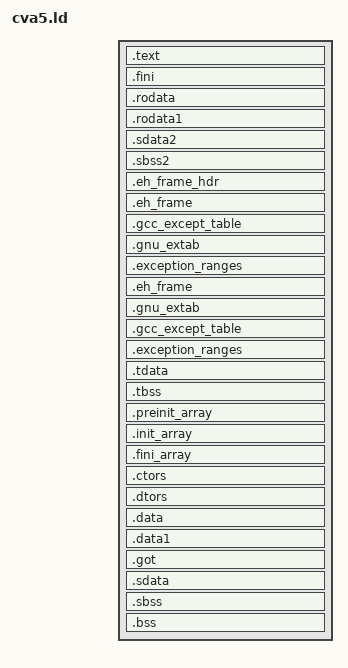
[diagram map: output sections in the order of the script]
/* Default linker script, for normal executables */
/* Copyright (C) 2014-2021 Free Software Foundation, Inc.
   Copying and distribution of this script, with or without modification,
   are permitted in any medium without royalty provided the copyright
   notice and this notice are preserved.  */
OUTPUT_ARCH(riscv)
ENTRY(_start)
/*STARTUP(crtbegin.o)*/
MEMORY
{
  ram : ORIGIN = (DEFINED(__mem_addr) ? __mem_addr : 0x80000000), LENGTH = (DEFINED(__mem_size) ? __mem_size : 128K)
}

SECTIONS
{
  PROVIDE(__stack = ORIGIN(ram) + LENGTH(ram));

  .text :
  {
    *(.text.start)
    *(.text.unlikely .text.unlikely.*)
    *(.text.startup .text.startup.*)
    *(.text .text.*)
    *(.gnu.linkonce.t.*)
  } > ram
  
  .fini           :
  {
    KEEP (*(SORT_NONE(.fini)))
  } > ram
  PROVIDE (__etext = .);
  PROVIDE (_etext = .);
  PROVIDE (etext = .);
  .rodata         : { *(.rodata .rodata.* .gnu.linkonce.r.*) } > ram
  .rodata1        : { *(.rodata1) } > ram
  .sdata2         :
  {
    *(.sdata2 .sdata2.* .gnu.linkonce.s2.*)
  } > ram
  .sbss2          : { *(.sbss2 .sbss2.* .gnu.linkonce.sb2.*) } > ram
  .eh_frame_hdr   : { *(.eh_frame_hdr) *(.eh_frame_entry .eh_frame_entry.*) } > ram
  .eh_frame       : ONLY_IF_RO { KEEP (*(.eh_frame)) *(.eh_frame.*) } > ram
  .gcc_except_table   : ONLY_IF_RO { *(.gcc_except_table .gcc_except_table.*) } > ram
  .gnu_extab   : ONLY_IF_RO { *(.gnu_extab*) } > ram
  /* These sections are generated by the Sun/Oracle C++ compiler.  */
  .exception_ranges   : ONLY_IF_RO { *(.exception_ranges*) } > ram
  /* Adjust the address for the data segment.  We want to adjust up to
     the same address within the page on the next page up.  */
  . = DATA_SEGMENT_ALIGN (CONSTANT (MAXPAGESIZE), CONSTANT (COMMONPAGESIZE));
  /* Exception handling  */
  .eh_frame       : ONLY_IF_RW { KEEP (*(.eh_frame)) *(.eh_frame.*) } > ram
  .gnu_extab      : ONLY_IF_RW { *(.gnu_extab) } > ram
  .gcc_except_table   : ONLY_IF_RW { *(.gcc_except_table .gcc_except_table.*) } > ram
  .exception_ranges   : ONLY_IF_RW { *(.exception_ranges*) } > ram
  /* Thread Local Storage sections  */
  .tdata	  :
   {
     PROVIDE_HIDDEN (__tdata_start = .);
     *(.tdata .tdata.* .gnu.linkonce.td.*)
   } > ram
  .tbss		  : { *(.tbss .tbss.* .gnu.linkonce.tb.*) *(.tcommon) } > ram
  .preinit_array    :
  {
    PROVIDE_HIDDEN (__preinit_array_start = .);
    KEEP (*(.preinit_array))
    PROVIDE_HIDDEN (__preinit_array_end = .);
  } > ram
  .init_array    :
  {
    PROVIDE_HIDDEN (__init_array_start = .);
    KEEP (*(SORT_BY_INIT_PRIORITY(.init_array.*) SORT_BY_INIT_PRIORITY(.ctors.*)))
    KEEP (*(.init_array EXCLUDE_FILE (*crtbegin.o *crtbegin?.o *crtend.o *crtend?.o ) .ctors))
    PROVIDE_HIDDEN (__init_array_end = .);
  } > ram
  .fini_array    :
  {
    PROVIDE_HIDDEN (__fini_array_start = .);
    KEEP (*(SORT_BY_INIT_PRIORITY(.fini_array.*) SORT_BY_INIT_PRIORITY(.dtors.*)))
    KEEP (*(.fini_array EXCLUDE_FILE (*crtbegin.o *crtbegin?.o *crtend.o *crtend?.o ) .dtors))
    PROVIDE_HIDDEN (__fini_array_end = .);
  } > ram
  .ctors          :
  {
    /* gcc uses crtbegin.o to find the start of
       the constructors, so we make sure it is
       first.  Because this is a wildcard, it
       doesn't matter if the user does not
       actually link against crtbegin.o; the
       linker won't look for a file to match a
       wildcard.  The wildcard also means that it
       doesn't matter which directory crtbegin.o
       is in.  */
    KEEP (*crtbegin.o(.ctors))
    KEEP (*crtbegin?.o(.ctors))
    /* We don't want to include the .ctor section from
       the crtend.o file until after the sorted ctors.
       The .ctor section from the crtend file contains the
       end of ctors marker and it must be last */
    KEEP (*(EXCLUDE_FILE (*crtend.o *crtend?.o ) .ctors))
    KEEP (*(SORT(.ctors.*)))
    KEEP (*(.ctors))
  } > ram
  .dtors          :
  {
    KEEP (*crtbegin.o(.dtors))
    KEEP (*crtbegin?.o(.dtors))
    KEEP (*(EXCLUDE_FILE (*crtend.o *crtend?.o ) .dtors))
    KEEP (*(SORT(.dtors.*)))
    KEEP (*(.dtors))
  } > ram
  .data           :
  {
    __DATA_BEGIN__ = .;
    *(.data .data.* .gnu.linkonce.d.*)
    SORT(CONSTRUCTORS)
  } > ram
  .data1          : { *(.data1) } > ram
  .got            : { *(.got.plt) *(.igot.plt) *(.got) *(.igot) } > ram
  /* We want the small data sections together, so single-instruction offsets
     can access them all, and initialized data all before uninitialized, so
     we can shorten the on-disk segment size.  */
  .sdata          :
  {
    __SDATA_BEGIN__ = .;
    *(.srodata.cst16) *(.srodata.cst8) *(.srodata.cst4) *(.srodata.cst2) *(.srodata .srodata.*)
    *(.sdata .sdata.* .gnu.linkonce.s.*)
  } > ram
  _edata = .; PROVIDE (edata = .);
  . = .;
  __bss_start = .;
  .sbss           :
  {
    *(.dynsbss)
    *(.sbss .sbss.* .gnu.linkonce.sb.*)
    *(.scommon)
  } > ram
  .bss            :
  {
   *(.dynbss)
   *(.bss .bss.* .gnu.linkonce.b.*)
   *(COMMON)
   /* Align here to ensure that the .bss section occupies space up to
      _end.  Align after .bss to ensure correct alignment even if the
      .bss section disappears because there are no input sections.
      FIXME: Why do we need it? When there is no .bss section, we do not
      pad the .data section.  */
   . = ALIGN(. != 0 ? 32 / 8 : 1);
  } > ram
  . = ALIGN(32 / 8);
  . = SEGMENT_START("ldata-segment", .);
  . = ALIGN(32 / 8);
  __BSS_END__ = .;
    __global_pointer$ = MIN(__SDATA_BEGIN__ + 0x800,
		            MAX(__DATA_BEGIN__ + 0x800, __BSS_END__ - 0x800));
  _end = .; PROVIDE (end = .);
  . = DATA_SEGMENT_END (.);


  PROVIDE( __end = __bss_end );
  PROVIDE( _end = __bss_end );
  PROVIDE( end = __bss_end );


  PROVIDE( __heap_start = __end );
  PROVIDE( __heap_end = __stack - (DEFINED(__stack_size) ? __stack_size : 0x800)  );
  PROVIDE( __heap_size = __heap_end - __heap_start );

  /DISCARD/ : { *(.note.GNU-stack) *(.gnu_debuglink) *(.gnu.lto_*) }
}
